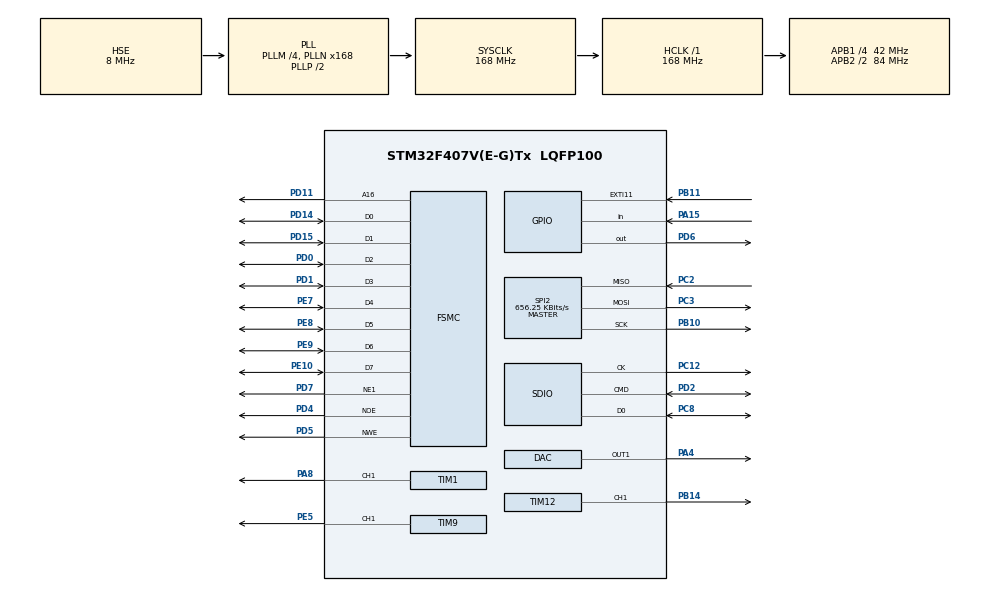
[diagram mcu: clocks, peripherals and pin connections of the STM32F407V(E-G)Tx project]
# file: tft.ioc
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DAC.DAC_Trigger=DAC_TRIGGER_T4_TRGO
Dma.DAC1.2.Direction=DMA_MEMORY_TO_PERIPH
Dma.DAC1.2.FIFOMode=DMA_FIFOMODE_DISABLE
Dma.DAC1.2.Instance=DMA1_Stream5
Dma.DAC1.2.MemDataAlignment=DMA_MDATAALIGN_BYTE
Dma.DAC1.2.MemInc=DMA_MINC_ENABLE
Dma.DAC1.2.Mode=DMA_CIRCULAR
Dma.DAC1.2.PeriphDataAlignment=DMA_PDATAALIGN_BYTE
Dma.DAC1.2.PeriphInc=DMA_PINC_DISABLE
Dma.DAC1.2.Priority=DMA_PRIORITY_HIGH
Dma.Request0=SDIO_RX
Dma.Request1=SDIO_TX
Dma.Request2=DAC1
Dma.SDIO_RX.0.Direction=DMA_PERIPH_TO_MEMORY
Dma.SDIO_RX.0.FIFOMode=DMA_FIFOMODE_ENABLE
Dma.SDIO_RX.0.FIFOThreshold=DMA_FIFO_THRESHOLD_FULL
Dma.SDIO_RX.0.Instance=DMA2_Stream3
Dma.SDIO_RX.0.MemBurst=DMA_MBURST_INC4
Dma.SDIO_RX.0.MemDataAlignment=DMA_MDATAALIGN_WORD
Dma.SDIO_RX.0.MemInc=DMA_MINC_ENABLE
Dma.SDIO_RX.0.Mode=DMA_PFCTRL
Dma.SDIO_RX.0.PeriphBurst=DMA_PBURST_INC4
Dma.SDIO_RX.0.PeriphDataAlignment=DMA_PDATAALIGN_WORD
Dma.SDIO_RX.0.PeriphInc=DMA_PINC_DISABLE
Dma.SDIO_RX.0.Priority=DMA_PRIORITY_HIGH
Dma.SDIO_TX.1.Direction=DMA_MEMORY_TO_PERIPH
Dma.SDIO_TX.1.FIFOMode=DMA_FIFOMODE_ENABLE
Dma.SDIO_TX.1.FIFOThreshold=DMA_FIFO_THRESHOLD_FULL
Dma.SDIO_TX.1.Instance=DMA2_Stream6
Dma.SDIO_TX.1.MemBurst=DMA_MBURST_INC4
Dma.SDIO_TX.1.MemDataAlignment=DMA_MDATAALIGN_WORD
Dma.SDIO_TX.1.MemInc=DMA_MINC_ENABLE
Dma.SDIO_TX.1.Mode=DMA_PFCTRL
Dma.SDIO_TX.1.PeriphBurst=DMA_PBURST_INC4
Dma.SDIO_TX.1.PeriphDataAlignment=DMA_PDATAALIGN_WORD
Dma.SDIO_TX.1.PeriphInc=DMA_PINC_DISABLE
Dma.SDIO_TX.1.Priority=DMA_PRIORITY_HIGH
FATFS.BSP.number=1
FATFS._FS_EXFAT=1
FATFS._MAX_SS=4096
FATFS._USE_LFN=2
FATFS0.BSP.STBoard=false
FATFS0.BSP.api=Unknown
FATFS0.BSP.i2caddr=0
FATFS0.BSP.instance=PA15
FATFS0.BSP.ip=GPIO
FATFS0.BSP.mode=Input
FATFS0.BSP.name=Detect_SDIO
FATFS0.BSP.solution=PA15
FREERTOS.Tasks01=defaultTask,24,128,StartDefaultTask,Default,NULL,Dynamic,NULL,NULL
FSMC.AddressSetupTime1=2
FSMC.DataSetupTime1=15
FSMC.ExtendedAddressSetupTime1=2
FSMC.ExtendedBusTurnAroundDuration1=3
FSMC.ExtendedDataSetupTime1=3
FSMC.ExtendedMode1=FSMC_EXTENDED_MODE_ENABLE
Mcu.Family=STM32F4
Mcu.Name=STM32F407V(E-G)Tx
Mcu.Package=LQFP100
NVIC.DMA1_Stream5_IRQn=true\:0\:0\:false\:false\:true\:true\:false\:true
NVIC.DMA2_Stream3_IRQn=true\:5\:0\:true\:false\:true\:true\:false\:true
NVIC.DMA2_Stream6_IRQn=true\:5\:0\:true\:false\:true\:true\:false\:true
NVIC.PriorityGroup=NVIC_PRIORITYGROUP_4
NVIC.SDIO_IRQn=true\:4\:0\:true\:false\:true\:false\:true\:true
NVIC.TIM2_IRQn=true\:0\:0\:false\:false\:true\:false\:false\:true
NVIC.TIM6_DAC_IRQn=true\:0\:0\:false\:false\:true\:false\:true\:true
NVIC.TimeBase=TIM2_IRQn
NVIC.TimeBaseIP=TIM2
PA13.Mode=Serial_Wire
PA13.Signal=SYS_JTMS-SWDIO
PA14.Mode=Serial_Wire
PA14.Signal=SYS_JTCK-SWCLK
PA15.GPIO_PuPd=GPIO_PULLDOWN
PA15.Signal=GPIO_Input
PA4.Signal=COMP_DAC1_group
PA8.GPIO_PuPd=GPIO_NOPULL
PA8.GPIO_Speed=GPIO_SPEED_FREQ_VERY_HIGH
PA8.Signal=S_TIM1_CH1
PB10.Mode=Full_Duplex_Master
PB10.Signal=SPI2_SCK
PB11.GPIO_ModeDefaultEXTI=GPIO_MODE_IT_RISING_FALLING
PB11.Signal=GPXTI11
PB14.GPIO_PuPd=GPIO_NOPULL
PB14.GPIO_Speed=GPIO_SPEED_FREQ_HIGH
PB14.Signal=S_TIM12_CH1
PC12.Mode=SD_1_bit
PC12.Signal=SDIO_CK
PC2.Mode=Full_Duplex_Master
PC2.Signal=SPI2_MISO
PC3.Mode=Full_Duplex_Master
PC3.Signal=SPI2_MOSI
PC8.GPIO_PuPd=GPIO_PULLUP
PC8.Mode=SD_1_bit
PC8.Signal=SDIO_D0
PD0.Mode=8b-d1
PD0.Signal=FSMC_D2
PD1.Mode=8b-d1
PD1.Signal=FSMC_D3
PD11.Mode=A16_1
PD11.Signal=FSMC_A16
PD14.Mode=8b-d1
PD14.Signal=FSMC_D0
PD15.Mode=8b-d1
PD15.Signal=FSMC_D1
PD2.GPIO_PuPd=GPIO_PULLUP
PD2.Mode=SD_1_bit
PD2.Signal=SDIO_CMD
PD4.Mode=Lcd1
PD4.Signal=FSMC_NOE
PD5.Mode=Lcd1
PD5.Signal=FSMC_NWE
PD6.Signal=GPIO_Output
PD7.Mode=NorPsramChipSelect1_1
PD7.Signal=FSMC_NE1
PE10.Mode=8b-d1
PE10.Signal=FSMC_D7
PE5.GPIO_PuPd=GPIO_NOPULL
PE5.GPIO_Speed=GPIO_SPEED_FREQ_VERY_HIGH
PE5.Signal=S_TIM9_CH1
PE7.Mode=8b-d1
PE7.Signal=FSMC_D4
PE8.Mode=8b-d1
PE8.Signal=FSMC_D5
PE9.Mode=8b-d1
PE9.Signal=FSMC_D6
PH0-OSC_IN.Mode=HSE-External-Oscillator
PH0-OSC_IN.Signal=RCC_OSC_IN
PH1-OSC_OUT.Mode=HSE-External-Oscillator
PH1-OSC_OUT.Signal=RCC_OSC_OUT
ProjectManager.HeapSize=0x200
ProjectManager.StackSize=0x400
ProjectManager.TargetToolchain=STM32CubeIDE
RCC.48MHZClocksFreq_Value=48000000
RCC.AHBFreq_Value=168000000
RCC.APB1CLKDivider=RCC_HCLK_DIV4
RCC.APB1Freq_Value=42000000
RCC.APB1TimFreq_Value=84000000
RCC.APB2CLKDivider=RCC_HCLK_DIV2
RCC.APB2Freq_Value=84000000
RCC.APB2TimFreq_Value=168000000
RCC.CortexFreq_Value=168000000
RCC.HCLKFreq_Value=168000000
RCC.HSE_VALUE=8000000
RCC.HSI_VALUE=16000000
RCC.LSE_VALUE=32768
RCC.PLLM=4
RCC.PLLN=168
RCC.PLLQ=7
RCC.PLLSourceVirtual=RCC_PLLSOURCE_HSE
RCC.SYSCLKFreq_VALUE=168000000
RCC.SYSCLKSource=RCC_SYSCLKSOURCE_PLLCLK
RCC.VCOOutputFreq_Value=336000000
SDIO.ClockDiv=4
SH.COMP_DAC1_group.0=DAC_OUT1,DAC_OUT1
SH.S_TIM12_CH1.0=TIM12_CH1,PWM Generation1 CH1
SH.S_TIM1_CH1.0=TIM1_CH1,PWM Generation1 CH1
SH.S_TIM9_CH1.0=TIM9_CH1,PWM Generation1 CH1
SPI2.BaudRatePrescaler=SPI_BAUDRATEPRESCALER_64
SPI2.CalculateBaudRate=656.25 KBits/s
SPI2.Direction=SPI_DIRECTION_2LINES
SPI2.Mode=SPI_MODE_MASTER
SPI2.VirtualType=VM_MASTER
STMicroelectronics.X-CUBE-TOUCHGFX.4.14.0.ApplicationCcGraphicsJjApplication=TouchGFXOoGenerator
TIM1.AutoReloadPreload=TIM_AUTORELOAD_PRELOAD_DISABLE
TIM1.AutomaticOutput=TIM_AUTOMATICOUTPUT_DISABLE
TIM1.Channel-PWM\ Generation1\ CH1=TIM_CHANNEL_1
TIM1.ClockDivision=TIM_CLOCKDIVISION_DIV1
TIM1.OCFastMode_PWM-PWM\ Generation1\ CH1=TIM_OCFAST_ENABLE
TIM1.Period=1200
TIM1.Prescaler=470
TIM1.Pulse-PWM\ Generation1\ CH1=0
TIM12.Channel-PWM\ Generation1\ CH1=TIM_CHANNEL_1
TIM4.TIM_MasterOutputTrigger=TIM_TRGO_UPDATE
TIM9.Channel-PWM\ Generation1\ CH1=TIM_CHANNEL_1
VP_FATFS_VS_SDIO.Mode=SDIO
VP_FREERTOS_VS_CMSIS_V2.Mode=CMSIS_V2
VP_SYS_VS_tim2.Mode=TIM2
VP_TIM1_VS_ClockSourceINT.Mode=Internal
VP_TIM4_VS_ClockSourceINT.Mode=Internal
board=custom

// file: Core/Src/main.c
/* USER CODE BEGIN Header */
/**
 ******************************************************************************
 * @file           : main.c
 * @brief          : Main program body
 ******************************************************************************
 * @attention
 *
 * <h2><center>&copy; Copyright (c) 2020 STMicroelectronics.
 * All rights reserved.</center></h2>
 *
 * This software component is licensed by ST under BSD 3-Clause license,
 * the "License"; You may not use this file except in compliance with the
 * License. You may obtain a copy of the License at:
 *                        opensource.org/licenses/BSD-3-Clause
 *
 ******************************************************************************
 */
/* USER CODE END Header */
#include "main.h"
#include "cmsis_os.h"
#include "dac.h"
#include "dma.h"
#include "fatfs.h"
#include "sdio.h"
#include "spi.h"
#include "tim.h"
#include "gpio.h"
#include "fsmc.h"

/* USER CODE BEGIN Includes */
#include <cmsis_os2.h>

#include "base.h"

/* USER CODE END Includes */

void SystemClock_Config(void);
void MX_FREERTOS_Init(void);

/* USER CODE BEGIN 0 */
extern osMessageQueueId_t SDQueueID;
void HAL_GPIO_EXTI_Callback(uint16_t GPIO_Pin) {
    int a = 0;
    a++;
}

/* USER CODE END 0 */

int main(void) {

    /* MCU Configuration--------------------------------------------------------*/

    /* Reset of all peripherals, Initializes the Flash interface and the Systick. */
    HAL_Init();

    /* Configure the system clock */
    SystemClock_Config();

    /* USER CODE BEGIN SysInit */
    __HAL_RCC_TIM1_CLK_ENABLE();
    /* USER CODE END SysInit */

    /* Initialize all configured peripherals */
    MX_GPIO_Init();
    MX_DMA_Init();
    MX_FSMC_Init();
    MX_DAC_Init();
    MX_SDIO_SD_Init();
    MX_FATFS_Init();
    MX_SPI2_Init();
    MX_TIM1_Init();
    MX_TIM9_Init();
    MX_TIM12_Init();
    MX_TIM4_Init();
    /* USER CODE BEGIN 2 */
    baseInit();
    /* USER CODE END 2 */

    /* Init scheduler */
    osKernelInitialize(); /* Call init function for freertos objects (in freertos.c) */
    MX_FREERTOS_Init();
    /* Start scheduler */
    osKernelStart();

    /* We should never get here as control is now taken by the scheduler */
    /* Infinite loop */
    while (1) {

    }
}

void SystemClock_Config(void) {
    RCC_OscInitTypeDef RCC_OscInitStruct = { 0 };
    RCC_ClkInitTypeDef RCC_ClkInitStruct = { 0 };

    /** Configure the main internal regulator output voltage
     */
    __HAL_RCC_PWR_CLK_ENABLE();
    __HAL_PWR_VOLTAGESCALING_CONFIG(PWR_REGULATOR_VOLTAGE_SCALE1);
    /** Initializes the RCC Oscillators according to the specified parameters
     * in the RCC_OscInitTypeDef structure.
     */
    RCC_OscInitStruct.OscillatorType = RCC_OSCILLATORTYPE_HSE;
    RCC_OscInitStruct.HSEState = RCC_HSE_ON;
    RCC_OscInitStruct.PLL.PLLState = RCC_PLL_ON;
    RCC_OscInitStruct.PLL.PLLSource = RCC_PLLSOURCE_HSE;
    RCC_OscInitStruct.PLL.PLLM = 4;
    RCC_OscInitStruct.PLL.PLLN = 168;
    RCC_OscInitStruct.PLL.PLLP = RCC_PLLP_DIV2;
    RCC_OscInitStruct.PLL.PLLQ = 7;
    if (HAL_RCC_OscConfig(&RCC_OscInitStruct) != HAL_OK) {
        Error_Handler();
    }
    /** Initializes the CPU, AHB and APB buses clocks
     */
    RCC_ClkInitStruct.ClockType = RCC_CLOCKTYPE_HCLK | RCC_CLOCKTYPE_SYSCLK | RCC_CLOCKTYPE_PCLK1 | RCC_CLOCKTYPE_PCLK2;
    RCC_ClkInitStruct.SYSCLKSource = RCC_SYSCLKSOURCE_PLLCLK;
    RCC_ClkInitStruct.AHBCLKDivider = RCC_SYSCLK_DIV1;
    RCC_ClkInitStruct.APB1CLKDivider = RCC_HCLK_DIV4;
    RCC_ClkInitStruct.APB2CLKDivider = RCC_HCLK_DIV2;

    if (HAL_RCC_ClockConfig(&RCC_ClkInitStruct, FLASH_LATENCY_5) != HAL_OK) {
        Error_Handler();
    }
}

void HAL_TIM_PeriodElapsedCallback(TIM_HandleTypeDef *htim) {
    if (htim->Instance == TIM2) {
        HAL_IncTick();
    }
}

void Error_Handler(void) {
    /* USER CODE BEGIN Error_Handler_Debug */
    /* User can add his own implementation to report the HAL error return state */
    baseErrorHandler("SYSTEM_ERROR");
    /* USER CODE END Error_Handler_Debug */
}

/************************ (C) COPYRIGHT STMicroelectronics *****END OF FILE****/
